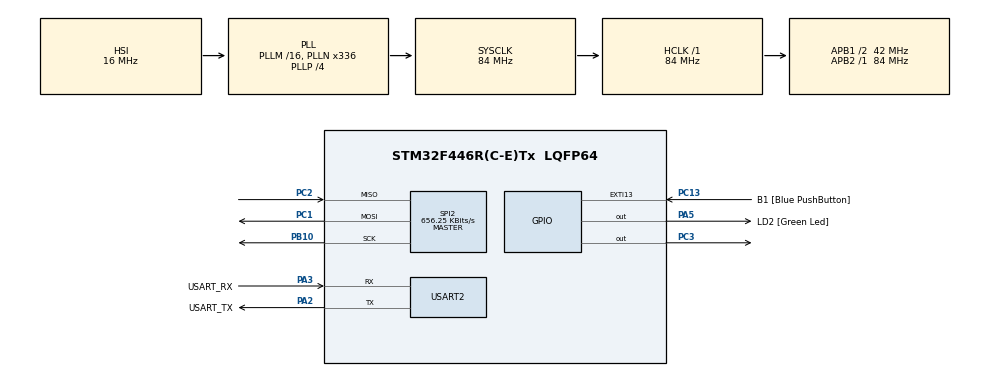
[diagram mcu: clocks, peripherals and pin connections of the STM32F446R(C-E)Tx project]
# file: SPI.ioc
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Mcu.Family=STM32F4
PH0-OSC_IN.Signal=RCC_OSC_IN
RCC.CortexFreq_Value=84000000
SPI2.VirtualType=VM_MASTER
PB10.Mode=Full_Duplex_Master
PA14.GPIO_Label=TCK
PC13.GPIO_Label=B1 [Blue PushButton]
RCC.SYSCLKSource=RCC_SYSCLKSOURCE_PLLCLK
ProjectManager.StackSize=0x400
TIM1.Prescaler=84-1
SPI2.CLKPolarity=SPI_POLARITY_HIGH
RCC.HCLKFreq_Value=84000000
RCC.APB2TimFreq_Value=84000000
PC3.Signal=GPIO_Output
RCC.AHBFreq_Value=84000000
SPI2.BaudRatePrescaler=SPI_BAUDRATEPRESCALER_64
PH0-OSC_IN.Mode=HSE-External-Oscillator
RCC.HSE_VALUE=8000000
PC14-OSC32_IN.Mode=LSE-External-Oscillator
PA14.Mode=Serial_Wire
SPI2.CalculateBaudRate=656.25 KBits/s
VP_TIM1_VS_ClockSourceINT.Mode=Internal
RCC.FLatency-AdvancedSettings=FLASH_LATENCY_2
PH1-OSC_OUT.Mode=HSE-External-Oscillator
Mcu.Package=LQFP64
SPI2.Mode=SPI_MODE_MASTER
USART2.VirtualMode=VM_ASYNC
PA2.GPIO_Label=USART_TX
SPI2.CLKPhase=SPI_PHASE_2EDGE
RCC.APB1TimFreq_Value=84000000
SPI2.Direction=SPI_DIRECTION_2LINES
TIM1.Period=1000-1
PA3.Signal=USART2_RX
PB3.GPIO_Label=SWO
PC15-OSC32_OUT.Mode=LSE-External-Oscillator
PC13.Signal=GPXTI13
PC2.Signal=SPI2_MISO
PC2.Mode=Full_Duplex_Master
RCC.APB1CLKDivider=RCC_HCLK_DIV2
PC14-OSC32_IN.Signal=RCC_OSC32_IN
PA3.Mode=Asynchronous
PA13.Signal=SYS_JTMS-SWDIO
ProjectManager.TargetToolchain=STM32CubeIDE
RCC.USBFreq_Value=168000000
PC15-OSC32_OUT.Signal=RCC_OSC32_OUT
PB10.Signal=SPI2_SCK
PA5.Signal=GPIO_Output
board=NUCLEO-F446RE
RCC.VCOOutputFreq_Value=336000000
RCC.APB2Freq_Value=84000000
PH1-OSC_OUT.Signal=RCC_OSC_OUT
PA13.Mode=Serial_Wire
Mcu.Name=STM32F446R(C-E)Tx
PA13.GPIO_Label=TMS
PA2.Signal=USART2_TX
RCC.48MHZClocksFreq_Value=84000000
PB3.Signal=SYS_JTDO-SWO
RCC.SYSCLKFreq_VALUE=84000000
PA5.GPIO_Label=LD2 [Green Led]
PC13.GPIO_ModeDefaultEXTI=GPIO_MODE_IT_FALLING
PA14.Signal=SYS_JTCK-SWCLK
ProjectManager.HeapSize=0x200
RCC.HSI_VALUE=16000000
RCC.PLLP=RCC_PLLP_DIV4
NVIC.PriorityGroup=NVIC_PRIORITYGROUP_0
RCC.PLLN=336
PA2.Mode=Asynchronous
RCC.APB1Freq_Value=42000000
PC1.Signal=SPI2_MOSI
PC1.Mode=Full_Duplex_Master
PA3.GPIO_Label=USART_RX

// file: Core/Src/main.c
/* USER CODE BEGIN Header */
/**
  ******************************************************************************
  * @file           : main.c
  * @brief          : Main program body
  ******************************************************************************
  * @attention
  *
  * <h2><center>&copy; Copyright (c) 2022 STMicroelectronics.
  * All rights reserved.</center></h2>
  *
  * This software component is licensed by ST under BSD 3-Clause license,
  * the "License"; You may not use this file except in compliance with the
  * License. You may obtain a copy of the License at:
  *                        opensource.org/licenses/BSD-3-Clause
  *
  ******************************************************************************
  */
/* USER CODE END Header */
#include "main.h"

/* USER CODE BEGIN Includes */
#include <stdio.h>
#include "mpu6500.h"
/* USER CODE END Includes */

SPI_HandleTypeDef hspi2;

TIM_HandleTypeDef htim1;

UART_HandleTypeDef huart2;

void SystemClock_Config(void);
static void MX_GPIO_Init(void);
static void MX_USART2_UART_Init(void);
static void MX_SPI2_Init(void);
static void MX_TIM1_Init(void);

int main(void)
{

  /* MCU Configuration--------------------------------------------------------*/

  /* Reset of all peripherals, Initializes the Flash interface and the Systick. */
  HAL_Init();

  /* Configure the system clock */
  SystemClock_Config();

  /* Initialize all configured peripherals */
  MX_GPIO_Init();
  MX_USART2_UART_Init();
  MX_SPI2_Init();
  MX_TIM1_Init();
  /* USER CODE BEGIN 2 */
  mpu6500_init();
  float gz;
  int count = 0;
  /* USER CODE END 2 */

  /* Infinite loop */
  while (1)
  {

    /* USER CODE BEGIN 3 */
	  gz = mpu6500_read_gyro_z();

	  if(count == 0){
		  printf("gz = %f\r\n", gz);
	  }
	  count = (count + 1) % 1000;
  }
  /* USER CODE END 3 */
}

void SystemClock_Config(void)
{
  RCC_OscInitTypeDef RCC_OscInitStruct = {0};
  RCC_ClkInitTypeDef RCC_ClkInitStruct = {0};

  /** Configure the main internal regulator output voltage
  */
  __HAL_RCC_PWR_CLK_ENABLE();
  __HAL_PWR_VOLTAGESCALING_CONFIG(PWR_REGULATOR_VOLTAGE_SCALE3);
  /** Initializes the RCC Oscillators according to the specified parameters
  * in the RCC_OscInitTypeDef structure.
  */
  RCC_OscInitStruct.OscillatorType = RCC_OSCILLATORTYPE_HSI;
  RCC_OscInitStruct.HSIState = RCC_HSI_ON;
  RCC_OscInitStruct.HSICalibrationValue = RCC_HSICALIBRATION_DEFAULT;
  RCC_OscInitStruct.PLL.PLLState = RCC_PLL_ON;
  RCC_OscInitStruct.PLL.PLLSource = RCC_PLLSOURCE_HSI;
  RCC_OscInitStruct.PLL.PLLM = 16;
  RCC_OscInitStruct.PLL.PLLN = 336;
  RCC_OscInitStruct.PLL.PLLP = RCC_PLLP_DIV4;
  RCC_OscInitStruct.PLL.PLLQ = 2;
  RCC_OscInitStruct.PLL.PLLR = 2;
  if (HAL_RCC_OscConfig(&RCC_OscInitStruct) != HAL_OK)
  {
    Error_Handler();
  }
  /** Initializes the CPU, AHB and APB buses clocks
  */
  RCC_ClkInitStruct.ClockType = RCC_CLOCKTYPE_HCLK|RCC_CLOCKTYPE_SYSCLK
                              |RCC_CLOCKTYPE_PCLK1|RCC_CLOCKTYPE_PCLK2;
  RCC_ClkInitStruct.SYSCLKSource = RCC_SYSCLKSOURCE_PLLCLK;
  RCC_ClkInitStruct.AHBCLKDivider = RCC_SYSCLK_DIV1;
  RCC_ClkInitStruct.APB1CLKDivider = RCC_HCLK_DIV2;
  RCC_ClkInitStruct.APB2CLKDivider = RCC_HCLK_DIV1;

  if (HAL_RCC_ClockConfig(&RCC_ClkInitStruct, FLASH_LATENCY_2) != HAL_OK)
  {
    Error_Handler();
  }
}

static void MX_SPI2_Init(void)
{

  /* SPI2 parameter configuration*/
  hspi2.Instance = SPI2;
  hspi2.Init.Mode = SPI_MODE_MASTER;
  hspi2.Init.Direction = SPI_DIRECTION_2LINES;
  hspi2.Init.DataSize = SPI_DATASIZE_8BIT;
  hspi2.Init.CLKPolarity = SPI_POLARITY_HIGH;
  hspi2.Init.CLKPhase = SPI_PHASE_2EDGE;
  hspi2.Init.NSS = SPI_NSS_SOFT;
  hspi2.Init.BaudRatePrescaler = SPI_BAUDRATEPRESCALER_64;
  hspi2.Init.FirstBit = SPI_FIRSTBIT_MSB;
  hspi2.Init.TIMode = SPI_TIMODE_DISABLE;
  hspi2.Init.CRCCalculation = SPI_CRCCALCULATION_DISABLE;
  hspi2.Init.CRCPolynomial = 10;
  if (HAL_SPI_Init(&hspi2) != HAL_OK)
  {
    Error_Handler();
  }

}

static void MX_TIM1_Init(void)
{

  TIM_ClockConfigTypeDef sClockSourceConfig = {0};
  TIM_MasterConfigTypeDef sMasterConfig = {0};

  htim1.Instance = TIM1;
  htim1.Init.Prescaler = 84-1;
  htim1.Init.CounterMode = TIM_COUNTERMODE_UP;
  htim1.Init.Period = 1000-1;
  htim1.Init.ClockDivision = TIM_CLOCKDIVISION_DIV1;
  htim1.Init.RepetitionCounter = 0;
  htim1.Init.AutoReloadPreload = TIM_AUTORELOAD_PRELOAD_DISABLE;
  if (HAL_TIM_Base_Init(&htim1) != HAL_OK)
  {
    Error_Handler();
  }
  sClockSourceConfig.ClockSource = TIM_CLOCKSOURCE_INTERNAL;
  if (HAL_TIM_ConfigClockSource(&htim1, &sClockSourceConfig) != HAL_OK)
  {
    Error_Handler();
  }
  sMasterConfig.MasterOutputTrigger = TIM_TRGO_RESET;
  sMasterConfig.MasterSlaveMode = TIM_MASTERSLAVEMODE_DISABLE;
  if (HAL_TIMEx_MasterConfigSynchronization(&htim1, &sMasterConfig) != HAL_OK)
  {
    Error_Handler();
  }

}

static void MX_USART2_UART_Init(void)
{

  huart2.Instance = USART2;
  huart2.Init.BaudRate = 115200;
  huart2.Init.WordLength = UART_WORDLENGTH_8B;
  huart2.Init.StopBits = UART_STOPBITS_1;
  huart2.Init.Parity = UART_PARITY_NONE;
  huart2.Init.Mode = UART_MODE_TX_RX;
  huart2.Init.HwFlowCtl = UART_HWCONTROL_NONE;
  huart2.Init.OverSampling = UART_OVERSAMPLING_16;
  if (HAL_UART_Init(&huart2) != HAL_OK)
  {
    Error_Handler();
  }

}

static void MX_GPIO_Init(void)
{
  GPIO_InitTypeDef GPIO_InitStruct = {0};

  /* GPIO Ports Clock Enable */
  __HAL_RCC_GPIOC_CLK_ENABLE();
  __HAL_RCC_GPIOH_CLK_ENABLE();
  __HAL_RCC_GPIOA_CLK_ENABLE();
  __HAL_RCC_GPIOB_CLK_ENABLE();

  /*Configure GPIO pin Output Level */
  HAL_GPIO_WritePin(GPIOC, GPIO_PIN_3, GPIO_PIN_RESET);

  /*Configure GPIO pin Output Level */
  HAL_GPIO_WritePin(LD2_GPIO_Port, LD2_Pin, GPIO_PIN_RESET);

  /*Configure GPIO pin : B1_Pin */
  GPIO_InitStruct.Pin = B1_Pin;
  GPIO_InitStruct.Mode = GPIO_MODE_IT_FALLING;
  GPIO_InitStruct.Pull = GPIO_NOPULL;
  HAL_GPIO_Init(B1_GPIO_Port, &GPIO_InitStruct);

  /*Configure GPIO pin : PC3 */
  GPIO_InitStruct.Pin = GPIO_PIN_3;
  GPIO_InitStruct.Mode = GPIO_MODE_OUTPUT_PP;
  GPIO_InitStruct.Pull = GPIO_NOPULL;
  GPIO_InitStruct.Speed = GPIO_SPEED_FREQ_LOW;
  HAL_GPIO_Init(GPIOC, &GPIO_InitStruct);

  /*Configure GPIO pin : LD2_Pin */
  GPIO_InitStruct.Pin = LD2_Pin;
  GPIO_InitStruct.Mode = GPIO_MODE_OUTPUT_PP;
  GPIO_InitStruct.Pull = GPIO_NOPULL;
  GPIO_InitStruct.Speed = GPIO_SPEED_FREQ_LOW;
  HAL_GPIO_Init(LD2_GPIO_Port, &GPIO_InitStruct);

}

void Error_Handler(void)
{
  __disable_irq();
  while (1)
  {
  }
}

/************************ (C) COPYRIGHT STMicroelectronics *****END OF FILE****/
